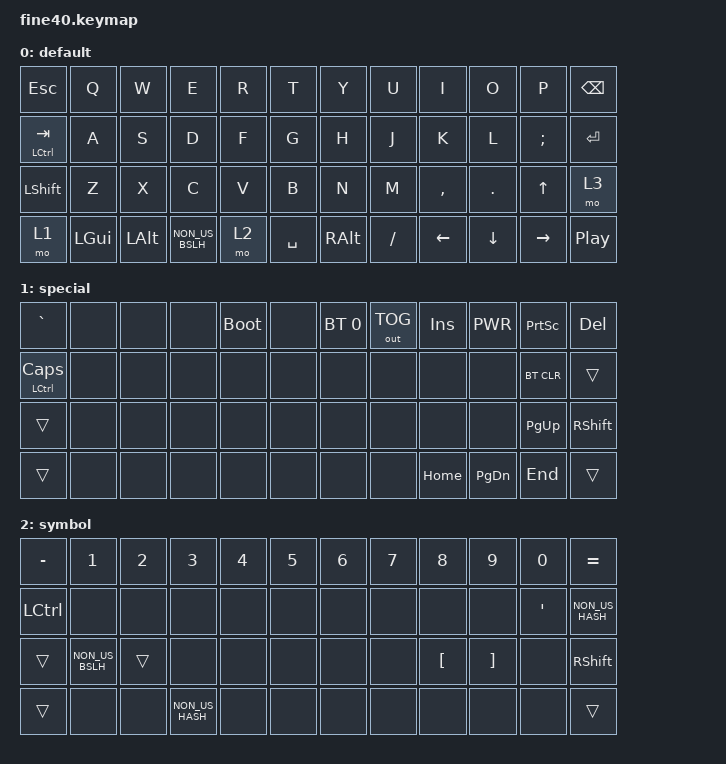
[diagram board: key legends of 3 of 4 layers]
/*
 * Aidan Smith (2021)
 *
 * SPDX-License-Identifier: MIT
 */

#include <behaviors.dtsi>
#include <dt-bindings/zmk/keys.h>
#include <dt-bindings/zmk/bt.h>
#include <dt-bindings/zmk/ext_power.h>
#include <dt-bindings/zmk/outputs.h>
#include <dt-bindings/zmk/pointing.h>

/ {

    behaviors {
        bt_encoder: bt_encoder {
            compatible = "zmk,behavior-sensor-rotate";
            label = "BT_ENCODER";
            #sensor-binding-cells = <0>;
            bindings = <&bt BT_NXT>, <&bt BT_PRV>;
        };
    };
    
	keymap {
		compatible = "zmk,keymap";

		default_layer {
			label = "default";
			bindings = <
				&kp ESC       &kp Q    &kp W           &kp E    &kp R    &kp T     &kp Y       &kp U     &kp I     &kp O     &kp P     &kp BSPC
				&mt LCTRL TAB &kp A    &kp S           &kp D    &kp F    &kp G     &kp H       &kp J     &kp K     &kp L     &kp SEMI  &kp RET
				&kp LSHFT     &kp Z    &kp X           &kp C    &kp V    &kp B     &kp N       &kp M     &kp COMMA &kp DOT   &kp UP    &mo 3
				&mo 1         &kp LGUI &kp LALT &kp NON_US_BSLH &mo 2    &kp SPACE &kp RALT    &kp FSLH  &kp LEFT  &kp DOWN  &kp RIGHT &kp C_PP
			>;

			sensor-bindings = <&inc_dec_kp DEL BSPC>;
		};

		special {
			label = "special";
			bindings = <
				&kp GRAVE      &none  &none  &none  &bootloader &none   &bt BT_SEL 0 &out OUT_TOG &kp INS    &kp K_PWR   &kp PSCRN  &kp DEL
				&mt LCTRL CLCK &none  &none  &none  &none       &none   &none        &none        &none      &none       &bt BT_CLR &trans
				&trans         &none  &none  &none  &none       &none   &none        &none        &none      &none       &kp PG_UP  &kp RSHFT
				&trans         &none  &none  &none  &none       &none   &none        &none      &kp HOME     &kp PG_DN  &kp END    &trans
			>;
			
			sensor-bindings = <&bt_encoder>; 
		};

		symbol {
			label = "symbol";
			bindings = <
				&kp MINUS &kp N1          &kp N2          &kp N3 &kp N4 &kp N5 &kp N6 &kp N7 &kp N8   &kp N9    &kp N0   &kp EQUAL
				&kp LCTRL &none           &none           &none  &none  &none  &none  &none  &none    &none     &kp SQT  &kp NON_US_HASH
				&trans    &kp NON_US_BSLH &trans          &none  &none  &none  &none  &none  &kp LBKT &kp RBKT  &none    &kp RSHFT
				&trans    &none           &none  &kp NON_US_HASH &none  &none  &none  &none  &none    &none     &none    &trans
			>;
			
			sensor-bindings = <&inc_dec_kp RIGHT LEFT>;
			};

		fn_layer {
			label = "fn";
			bindings = <
				&kp F1    &kp F2     &kp F3     &kp F4     &kp F5     &kp F6 &kp F7  &kp F8  &kp F9  &kp F10 &kp F11 &kp F12 
				&kp LCTRL &none      &none      &none      &none      &none  &none   &none   &none   &none   &none   &trans
				&trans    &none      &none      &none      &none      &none  &none   &none   &msc SCRL_UP   &msc SCRL_DOWN   &mmv MOVE_UP   &trans
				&trans    &trans     &trans     &trans     &trans     &mkp MB1 &trans  &mkp MB2  &mmv MOVE_LEFT  &mmv MOVE_DOWN  &mmv MOVE_RIGHT &mmv MOVE_UP &ext_power EP_ON
			>;
			
			sensor-bindings = <&inc_dec_kp DOWN UP>	;
		};
	};
};
